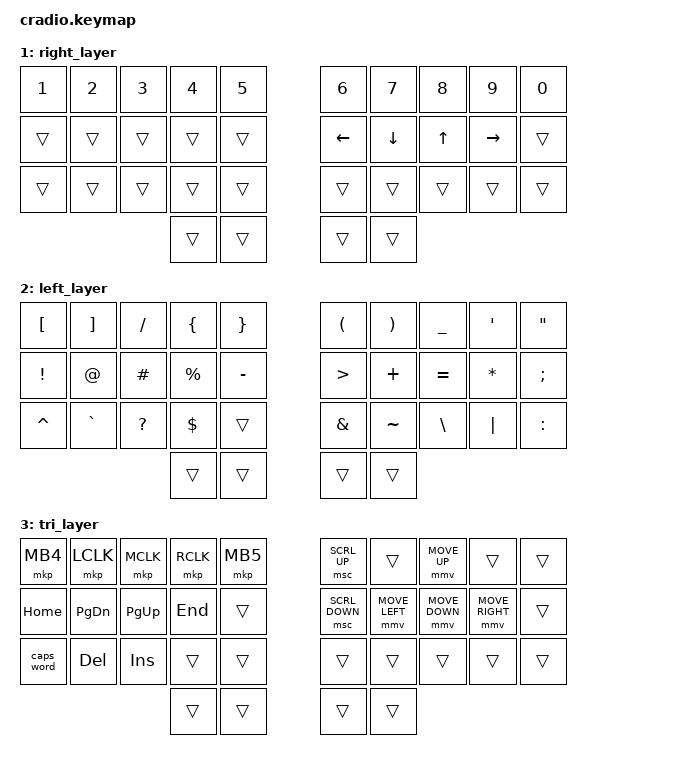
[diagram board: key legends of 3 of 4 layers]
// Copyright (c) 2022 The ZMK Contributors
// SPDX-License-Identifier: MIT

#include <behaviors.dtsi>
#include <dt-bindings/zmk/keys.h>
#include <dt-bindings/zmk/pointing.h>
#include <dt-bindings/zmk/behaviors.h>
// Home row mods macro
#define HRML(k1,k2,k3,k4) &ht LSHFT k1  &ht LALT k2  &ht LCTRL k3  &ht LGUI k4
#define HRMR(k1,k2,k3,k4) &ht RGUI k1  &ht RCTRL k2  &ht RALT k3  &ht RSHFT k4


/ {
    behaviors {
        ht: hold_tap {
            compatible = "zmk,behavior-hold-tap";
            #binding-cells = <2>;
            flavor = "balanced";
            tapping-term-ms = <180>;
            quick-tap-ms = <175>;
            require-prior-idle-ms = <150>;
            hold-trigger-on-release;
            bindings = <&kp>, <&kp>;
        };
        lt: layer_tap {
           compatible = "zmk,behavior-hold-tap";
           #binding-cells = <2>;
           flavor = "balanced";
           tapping-term-ms = <150>;
           quick-tap-ms = <175>;
           hold-trigger-on-release;
           bindings = <&mo>, <&kp>;
        };   
    };

    conditional_layers {
        compatible = "zmk,conditional-layers";
        tri_layer {
            if-layers = <1 2>;
            then-layer = <3>;
        };
    };

    keymap {
        compatible = "zmk,keymap";
        default_layer {
            bindings = <
        //╭──────────┬──────────┬──────────┬──────────┬──────────╮   ╭──────────┬──────────┬──────────┬──────────┬──────────╮
        //│  Q       │  W       │  E       │  R       │  T       │   │  Y       │  U       │  I       │  O       │  P       │
            &kp Q      &kp W      &kp E      &kp R      &kp T          &kp Y      &kp U      &kp I      &kp O      &kp P
        //├──────────┼──────────┼──────────┼──────────┼──────────┤   ├──────────┼──────────┼──────────┼──────────┼──────────┤
        //│  A       │  S       │  D       │  F       │  G       │   │  H       │  J       │  K       │  L       │ ' "      │
            &kp A      &kp S      &kp D      &kp F      &kp G          &kp H      &kp J      &kp K      &kp L      &kp SQT
        //├──────────┼──────────┼──────────┼──────────┼──────────┤   ├──────────┼──────────┼──────────┼──────────┼──────────┤
        //│  Z       │  X       │  C       │  V       │  B       │   │  N       │  M       │ , <      │ . >      │          │
            HRML(Z,        X,         C,         V)      &kp B         &kp N      HRMR(M,      COMMA,     DOT,       ESC)
        //╰──────────┴──────────┴──────────┼──────────┼──────────┤   ├──────────┼──────────┼──────────┴──────────┴──────────╯
        //                                 │          │          │   │          │          │
                                             &lt 2 TAB   &kp ENTER     &kp SPACE  &lt 1 BSPC

        //                                 ╰──────────┴──────────╯   ╰──────────┴──────────╯
            >;
        };

        right_layer {
            bindings = <
        //╭──────────┬──────────┬──────────┬──────────┬──────────╮   ╭──────────┬──────────┬──────────┬──────────┬──────────╮
        //│  1       │  2       │  3       │  4       │  5       │   │  6       │  7       │  8       │  9       │   0      │
            &kp N1     &kp N2     &kp N3     &kp N4     &kp N5         &kp N6     &kp N7     &kp N8     &kp N9      &kp N0
        //├──────────┼──────────┼──────────┼──────────┼──────────┤   ├──────────┼──────────┼──────────┼──────────┼──────────┤
        //│          │          │          │          │          │   │ LEFT     │ DOWN     │ UP       │ RIGHT    │          │
            &trans     &trans     &trans     &trans     &trans         &kp LEFT   &kp DOWN   &kp UP     &kp RIGHT   &trans 
        //├──────────┼──────────┼──────────┼──────────┼──────────┤   ├──────────┼──────────┼──────────┼──────────┼──────────┤
        //│          │          │          │          │          │   │          │          │          │          │          │
           &trans      &trans     &trans     &trans     &trans          &trans     &trans     &trans     &trans     &trans
        //╰──────────┴──────────┴──────────┼──────────┼──────────┤   ├──────────┼──────────┼──────────┴──────────┴──────────╯
        //                                 │          │          │   │          │          │
                                             &trans     &trans          &trans     &trans
        //                                 ╰──────────┴──────────╯   ╰──────────┴──────────╯
            >;
        };

        left_layer {
            bindings = <
        //╭──────────┬──────────┬──────────┬──────────┬──────────╮   ╭──────────┬──────────┬──────────┬──────────┬──────────╮
        //│  [       │  ]       │  /       │  {       │  }       │   │  (       │  )       │  _       │  '       │  "       │  
            &kp LBKT   &kp RBKT   &kp FSLH   &kp LBRC   &kp RBRC       &kp LPAR   &kp RPAR   &kp UNDER  &kp APOS   &kp DQT
        //├──────────┼──────────┼──────────┼──────────┼──────────┤   ├──────────┼──────────┼──────────┼──────────┼──────────┤
        //│  !       │  @       │  #       │  %       │  -       │   │  >       │  +       │  =       │  *       │  ;       │
            &kp EXCL   &kp AT     &kp HASH   &kp PRCNT  &kp MINUS      &kp GT     &kp PLUS   &kp EQUAL  &kp ASTRK &kp SEMI
        //├──────────┼──────────┼──────────┼──────────┼──────────┤   ├──────────┼──────────┼──────────┼──────────┼──────────┤
        //│  ^       │  `       │  ?       │  $       │          │   │  &       │  ~       │  \       │  |       │  :       │
            &kp CARET  &kp GRAVE  &kp QMARK  &kp DLLR   &trans         &kp AMPS   &kp TILDE  &kp BACKSLASH &kp PIPE   &kp COLON
        //╰──────────┴──────────┴──────────┼──────────┼──────────┤   ├──────────┼──────────┼──────────┴──────────┴──────────╯
        //                                 │          │          │   │          │          │
                                             &trans     &trans         &trans     &trans
        //                                 ╰──────────┴──────────╯   ╰──────────┴──────────╯
            >;
        };

        tri_layer {
            bindings = <
        //╭──────────┬──────────┬──────────┬──────────┬──────────╮   ╭──────────┬──────────┬──────────┬──────────┬──────────╮
        //│ 4        │ L        │ M        │ R        │ 5        │   │          │          │          │          │          │
            &mkp MB4   &mkp LCLK  &mkp MCLK  &mkp RCLK  &mkp MB5       &msc SCRL_UP &trans     &mmv MOVE_UP &trans     &trans
        //├──────────┼──────────┼──────────┼──────────┼──────────┤   ├──────────┼──────────┼──────────┼──────────┼──────────┤
        //│ HOME     │ PAGE DN  │ PAGE UP  │ END      │          │   │          │          │          │          │          │
            &kp HOME   &kp PG_DN  &kp PG_UP  &kp END    &trans         &msc SCRL_DOWN &mmv MOVE_LEFT &mmv MOVE_DOWN &mmv MOVE_RIGHT &trans
        //├──────────┼──────────┼──────────┼──────────┼──────────┤   ├──────────┼──────────┼──────────┼──────────┼──────────┤
        //│ CAPS     │ DEL      │ INSERT   │          │          │   │          │          │          │          │          │
            &caps_word &kp DEL    &kp INSERT &trans     &trans         &trans     &trans     &trans &trans     &trans
        //╰──────────┴──────────┴──────────┼──────────┼──────────┤   ├──────────┼──────────┼──────────┴──────────┴──────────╯
        //                                 │          │          │   │          │          │
                                             &trans     &trans         &trans     &trans
        //                                 ╰──────────┴──────────╯   ╰──────────┴──────────╯
            >;
        };
    };
};
